# EQEP0_REG register map
Vendor: Texas Instruments
Peripheral module from a debugger description file (folder am65x).
Registers are 32-bit, read-write, reset 0x0 unless marked. A register's access mark holds for its fields unless they carry their own. Offsets are as the file gives them; lines under a group give offsets from that group; [hi:lo] are bit positions; {n}, {i} and the like mark numbered series; 'fields as' and 'values as' point back to an identical list; <NAME> marks a mode.

## EQEP0_REG
0x00 EQEP_QPOSCNT
  [31:0] QPOSCNT — This 32 bit position counter register counts up/down on every EQEP pulse based on direction input. This counter acts as a position integrator whose count value is proportional to position from a give reference point.
0x04 EQEP_QPOSINIT
  [31:0] QPOSINIT — This register contains the position value that is used to initialize the position counter based on external strobe or index event. The position counter can be initialized through software.
0x08 EQEP_QPOSMAX
  [31:0] QPOSMAX — This register contains the maximum position counter value.
0x0C EQEP_QPOSCMP
  [31:0] QPOSCMP — The position-compare value in this register is compared with the position counter (
0x10 EQEP_QPOSILAT ro
  [31:0] QPOSILAT — The position-counter value is latched into this register on an index event as defined by the
0x14 EQEP_QPOSSLAT ro
  [31:0] QPOSSLAT — The position-counter value is latched into this register on strobe event as defined by the
0x18 EQEP_QPOSLAT ro
  [31:0] QPOSLAT — The position-counter value is latched into this register on unit time out event.
0x1C EQEP_QUTMR
  [31:0] QUTMR — This register acts as time base for unit time event generation. When this timer value matches with unit time period value, unit time event is generated.
0x20 EQEP_QUPRD
  [31:0] QUPRD — This register contains the period count for unit timer to generate periodic unit time events to latch the EQEP position information at periodic interval and optionally to generate interrupt.
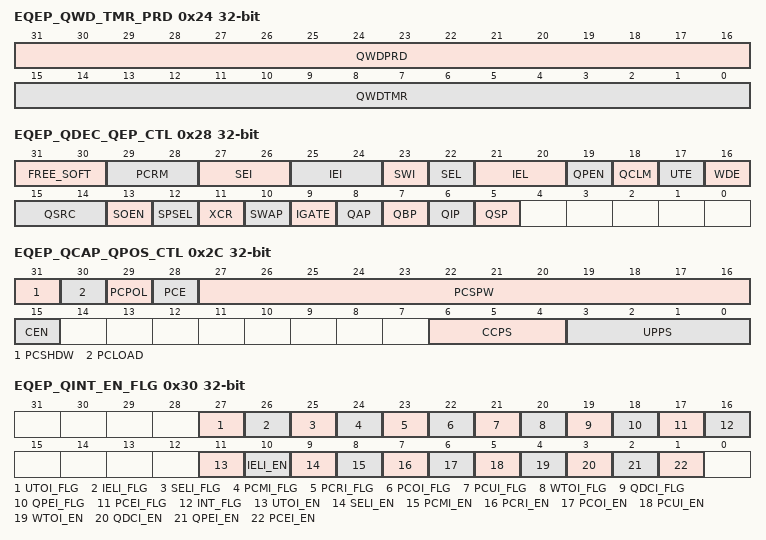
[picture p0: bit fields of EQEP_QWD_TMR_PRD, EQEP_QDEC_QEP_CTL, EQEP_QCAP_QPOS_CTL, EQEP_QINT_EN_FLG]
0x24 EQEP_QWD_TMR_PRD
  [31:16] QWDPRD — This field contains the time-out count for the EQEP peripheral watch dog timer. When the watch dog timer value matches with the watch dog period value, status flag is set to indicate the stall.
  [15:0] QWDTMR — This field acts as time base for watch dog to detect motor stalls. When this timer value matches with watch dog period value, watch dog timeout interrupt is generated. This register is reset upon edge transition in quadrature-clock indicating the motion.
0x28 EQEP_QDEC_QEP_CTL access per field
  [31:30] FREE_SOFT rw — Emulation Control Bits. In the values 0 through 3 listed below, x is different for the four following behaviors. EQEP_QPOSCNT behavior, x refers to the Position counter. EQEP_QWD_TMR_PRD behavior, x refers to the Watchdog counter. EQEP_QUTMR behavior, x refers to the Unit timer. EQEP_QCTMR behavior, x refers to the Capture timer. 0h = x stops immediately. For 1h = For QCTMR behavior, x continues to count until the next unit period event. 2h = x is unaffected by emulation suspend. 3h = x is unaffected by emulation suspend.
  [29:28] PCRM rw — Position counter reset mode 0h = Position counter reset on an index event 1h = Position counter reset on the maximum position 2h = Position counter resets once on the first index event 3h = Position counter reset on a unit time event
  [27:26] SEI rw — Strobe event initialization of position counter 0h = Does nothing (action disabled) 1h = Does nothing (action disabled) 2h = Initializes the position counter on rising edge of the QEPS signal 3h = Clockwise Direction: Initializes the position counter on the rising edge of QEPS strobe. Counter Clockwise Direction: Initializes the position counter on the falling edge of QEPS strobe
  [25:24] IEI rw — Index event initialization of position counter 0h = Do nothing (action disabled) 1h = Do nothing (action disabled) 2h = Initializes the position counter on the rising edge of the QEPI signal (QPOSCNT = QPOSINIT) 3h = Initializes the position counter on the falling edge of QEPI signal (QPOSCNT = QPOSINIT)
  [23] SWI rw — Software initialization of position counter 0h = Do nothing (action disabled) 1h = Initialize position counter, this bit is cleared automatically
  [22] SEL rw — Strobe event latch of position counter 0h = The position counter is latched on the rising edge of QEPS strobe (QPOSSLAT = POSCCNT). Latching on the falling edge can be done by inverting the strobe input using the QSP bit in the 1h = Clockwise Direction: Position counter is latched on rising edge of QEPS strobe. Counter Clockwise Direction: Position counter is latched on falling edge of QEPS strobe.
  [21:20] IEL rw — Index event latch of position counter (software index marker) 0h = Reserved 1h = Latches position counter on rising edge of the index signal 2h = Latches position counter on falling edge of the index signal 3h = Software index marker. Latches the position counter and quadrature direction flag on index event marker. The position counter is latched to theEQEP_QPOSILAT register and the direction flag is latched in the EQEP_QEPSTS[QDLF] bit. This mode is useful for software index marking.
  [19] QPEN rw — Quadrature position counter enable/software reset 0h = Reset the EQEP peripheral internal operating flags/read-only registers. Control/configuration registers are not disturbed by a software reset. 1h = EQEP position counter is enabled
  [18] QCLM rw — EQEP capture latch mode 0h = Latch on position counter read by CPU. Capture timer and capture period values are latched into EQEP_QCTMRLAT and EQEP_QCPRDLAT registers when CPU reads the EQEP_QPOSCNT register. 1h = Latch on unit time out. Position counter, capture timer and capture period values are latched intoEQEP_QPOSLAT, EQEP_QCTMRLAT and EQEP_QCPRDLAT registers on unit time out.
  [17] UTE rw — EQEP unit timer enable 0h = Disable EQEP unit timer 1h = Enable unit timer
  [16] WDE rw — EQEP watchdog enable 0h = Disable the EQEP watchdog timer 1h = Enable the EQEP watchdog timer
  [15:14] QSRC rw — Position-counter source selection. 0h = Quadrature count mode (QCLK = iCLK, QDIR = iDIR) 1h = Direction-count mode (QCLK = xCLK, QDIR = xDIR) 2h = UP count mode for frequency measurement (QCLK = xCLK, QDIR = 1) 3h = DOWN count mode for frequency measurement (QCLK = xCLK, QDIR = 0)
  [13] SOEN rw — Sync output-enable 0h = Disable position-compare sync output 1h = Enable position-compare sync output
  [12] SPSEL rw — Sync output pin selection 0h = Index pin is used for sync output 1h = Strobe pin is used for sync output
  [11] XCR rw — External clock rate 0h = 2x resolution: Count the rising/falling edge 1h = 1x resolution: Count the rising edge only
  [10] SWAP rw — Swap quadrature clock inputs. This swaps the input to the quadrature decoder, reversing the counting direction. 0h = Quadrature-clock inputs are not swapped 1h = Quadrature-clock inputs are swapped
  [9] IGATE rw — Index pulse gating option 0h = Disable gating of Index pulse 1h = Gate the index pin with strobe
  [8] QAP rw — QEPA input polarity 0h = No effect 1h = Negates QEPA input
  [7] QBP rw — QEPB input polarity 0h = No effect 1h = Negates QEPB input
  [6] QIP rw — QEPI input polarity 0h = No effect 1h = Negates QEPI input
  [5] QSP rw — QEPS input polarity 0h = No effect 1h = Negates QEPS input
0x2C EQEP_QCAP_QPOS_CTL access per field
  [31] PCSHDW rw — Position-compare shadow enable 0h = Shadow disabled, load Immediate 1h = Shadow enabled
  [30] PCLOAD rw — Position-compare shadow load mode 0h = Load on QPOSCNT = 0 1h = Load when QPOSCNT = QPOSCMP
  [29] PCPOL rw — Polarity of sync output 0h = Active HIGH pulse output 1h = Active LOW pulse output
  [28] PCE rw — Position-compare enable/disable 0h = Disable position compare unit 1h = Enable position compare unit
  [27:16] PCSPW rw — Select-position-compare sync output pulse width ... 0h = 1 × 4 × EQEP_FICLK cycles 1h = 2 × 4 × EQEP_FICLK cycles 2h = 3 × 4 × EQEP_FICLK cycles to 4096 × 4 × EQEP_FICLK cycles FFFh = 3 × 4 × EQEP_FICLK cycles to 4096 × 4 × EQEP_FICLK cycles
  [15] CEN rw — Enable EQEP capture 0h = EQEP capture unit is disabled 1h = EQEP capture unit is enabled
  [6:4] CCPS rw — EQEP capture timer clock prescaler 0h = CAPCLK = EQEP_FICLK/1 1h = CAPCLK = EQEP_FICLK/2 2h = CAPCLK = EQEP_FICLK/4 3h = CAPCLK = EQEP_FICLK/8 4h = CAPCLK = EQEP_FICLK/16 5h = CAPCLK = EQEP_FICLK/32 6h = CAPCLK = EQEP_FICLK/64 7h = CAPCLK = EQEP_FICLK/128
  [3:0] UPPS rw — Unit position event prescaler 0h = UPEVNT = QCLK/1 1h = UPEVNT = QCLK/2 2h = UPEVNT = QCLK/4 3h = UPEVNT = QCLK/8 4h = UPEVNT = QCLK/16 5h = UPEVNT = QCLK/32 6h = UPEVNT = QCLK/64 7h = UPEVNT = QCLK/128 8h = UPEVNT = QCLK/256 9h = UPEVNT = QCLK/512 Ah = UPEVNT = QCLK/1024 Bh = UPEVNT = QCLK/2048 Ch = Reserved Dh = Reserved Eh = Reserved Fh = Reserved
0x30 EQEP_QINT_EN_FLG access per field
  [27] UTOI_FLG ro — Unit time out interrupt flag 0h = No interrupt generated 1h = Set by EQEP unit timer period match
  [26] IELI_FLG ro — Index event latch interrupt flag 0h = No interrupt generated 1h = This bit is set after latching the
  [25] SELI_FLG ro — Strobe event latch interrupt flag 0h = No interrupt generated 1h = This bit is set after latching theEQEP_QPOSSLAT
  [24] PCMI_FLG ro — EQEP compare match event interrupt flag 0h = No interrupt generated 1h = This bit is set on position-compare match
  [23] PCRI_FLG ro — Position-compare ready interrupt flag 0h = No interrupt generated 1h = This bit is set after transferring the shadow register value to the active position compare register.
  [22] PCOI_FLG ro — Position counter overflow interrupt flag 0h = No interrupt generated 1h = This bit is set on position counter overflow.
  [21] PCUI_FLG ro — Position counter underflow interrupt flag 0h = No interrupt generated 1h = This bit is set on position counter underflow.
  [20] WTOI_FLG ro — Watchdog timeout interrupt flag 0h = No interrupt generated 1h = Set by watch dog timeout
  [19] QDCI_FLG ro — Quadrature direction change interrupt flag 0h = No interrupt generated 1h = This bit is set during change of direction
  [18] QPEI_FLG ro — Quadrature phase error interrupt flag 0h = No interrupt generated 1h = Set on simultaneous transition of QEPA and QEPB
  [17] PCEI_FLG ro — Position counter error interrupt flag 0h = No interrupt generated 1h = Position counter error
  [16] INT_FLG ro — Global interrupt status flag 0h = No interrupt generated 1h = Interrupt was generated
  [11] UTOI_EN rw — Unit time out interrupt enable 0h = Interrupt is disabled 1h = Interrupt is enabled
  [10] IELI_EN rw — Index event latch interrupt enable 0h = Interrupt is disabled 1h = Interrupt is enabled
  [9] SELI_EN rw — Strobe event latch interrupt enable 0h = Interrupt is disabled 1h = Interrupt is enabled
  [8] PCMI_EN rw — Position-compare match interrupt enable 0h = Interrupt is disabled 1h = Interrupt is enabled
  [7] PCRI_EN rw — Position-compare ready interrupt enable 0h = Interrupt is disabled 1h = Interrupt is enabled
  [6] PCOI_EN rw — Position counter overflow interrupt enable 0h = Interrupt is disabled 1h = Interrupt is enabled
  [5] PCUI_EN rw — Position counter underflow interrupt enable 0h = Interrupt is disabled 1h = Interrupt is enabled
  [4] WTOI_EN rw — Watchdog time out interrupt enable 0h = Interrupt is disabled 1h = Interrupt is enabled
  [3] QDCI_EN rw — Quadrature direction change interrupt enable 0h = Interrupt is disabled 1h = Interrupt is enabled
  [2] QPEI_EN rw — Quadrature phase error interrupt enable 0h = Interrupt is disabled 1h = Interrupt is enabled
  [1] PCEI_EN rw — Position counter error interrupt enable 0h = Interrupt is disabled 1h = Interrupt is enabled
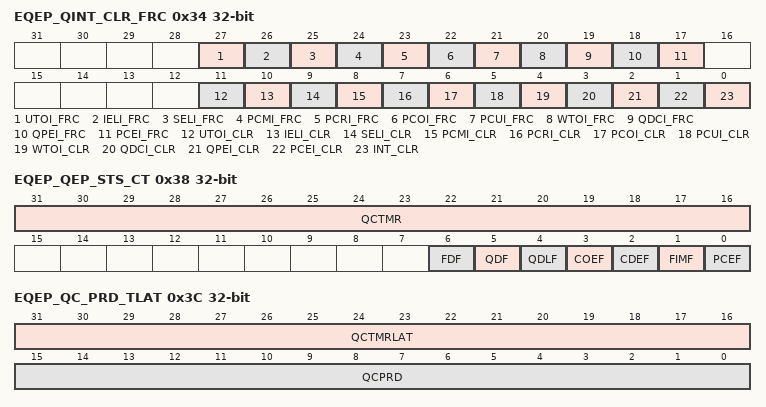
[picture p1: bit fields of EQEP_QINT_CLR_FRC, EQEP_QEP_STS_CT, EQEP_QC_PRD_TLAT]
0x34 EQEP_QINT_CLR_FRC access not given
  [27] UTOI_FRC — Force unit time out interrupt Read 0h = No effect Write 1h = Force the interrupt (access RW1S)
  [26] IELI_FRC — Force index event latch interrupt Read 0h = No effect Write 1h = Force the interrupt (access RW1S)
  [25] SELI_FRC — Force strobe event latch interrupt Read 0h = No effect Write 1h = Force the interrupt (access RW1S)
  [24] PCMI_FRC — Force position-compare match interrupt Read 0h = No effect Write 1h = Force the interrupt (access RW1S)
  [23] PCRI_FRC — Force position-compare ready interrupt Read 0h = No effect Write 1h = Force the interrupt (access RW1S)
  [22] PCOI_FRC — Force position counter overflow interrupt Read 0h = No effect Write 1h = Force the interrupt (access RW1S)
  [21] PCUI_FRC — Force position counter underflow interrupt Read 0h = No effect Write 1h = Force the interrupt (access RW1S)
  [20] WTOI_FRC — Force watchdog time out interrupt Read 0h = No effect Write 1h = Force the interrupt (access RW1S)
  [19] QDCI_FRC — Force quadrature direction change interrupt Read 0h = No effect Write 1h = Force the interrupt (access RW1S)
  [18] QPEI_FRC — Force quadrature phase error interrupt Read 0h = No effect Write 1h = Force the interrupt (access RW1S)
  [17] PCEI_FRC — Force position counter error interrupt Read 0h = No effect Write 1h = Force the interrupt (access RW1S)
  [11] UTOI_CLR — Clear unit time out interrupt flag Read 0h = No effect Write 1h = Clears the interrupt flag (access RW1C)
  [10] IELI_CLR — Clear index event latch interrupt flag Read 0h = No effect Write 1h = Clears the interrupt flag (access RW1C)
  [9] SELI_CLR — Clear strobe event latch interrupt flag Read 0h = No effect Write 1h = Clears the interrupt flag (access RW1C)
  [8] PCMI_CLR — Clear EQEP compare match event interrupt flag Read 0h = No effect Write 1h = Clears the interrupt flag (access RW1C)
  [7] PCRI_CLR — Clear position-compare ready interrupt flag Read 0h = No effect Write 1h = Clears the interrupt flag (access RW1C)
  [6] PCOI_CLR — Clear position counter overflow interrupt flag Read 0h = No effect Write 1h = Clears the interrupt flag (access RW1C)
  [5] PCUI_CLR — Clear position counter underflow interrupt flag Read 0h = No effect Write 1h = Clears the interrupt flag (access RW1C)
  [4] WTOI_CLR — Clear watchdog timeout interrupt flag Read 0h = No effect Write 1h = Clears the interrupt flag (access RW1C)
  [3] QDCI_CLR — Clear quadrature direction change interrupt flag Read 0h = No effect Write 1h = Clears the interrupt flag (access RW1C)
  [2] QPEI_CLR — Clear quadrature phase error interrupt flag Read 0h = No effect Write 1h = Clears the interrupt flag (access RW1C)
  [1] PCEI_CLR — Clear position counter error interrupt flag Read 0h = No effect Write 1h = Clears the interrupt flag (access RW1C)
  [0] INT_CLR — Global interrupt clear flag Read 0h = No effect Write 1h = Clears the interrupt flag and enables further interrupts to be generated if an event flags is set to 1. (access RW1C)
0x38 EQEP_QEP_STS_CT access not given
  [31:16] QCTMR rw — This field provides time base for edge capture unit.
  [6] FDF ro — Direction on the first index marker. Status of the direction is latched on the first index event marker. 0h = Counter-clockwise rotation (or reverse movement) on the first index event 1h = Clockwise rotation (or forward movement) on the first index event
  [5] QDF ro — Quadrature direction flag 0h = Counter-clockwise rotation (or reverse movement) 1h = Clockwise rotation (or forward movement)
  [4] QDLF ro — EQEP direction latch flag. Status of direction is latched on every index event marker. 0h = Counter-clockwise rotation (or reverse movement) on index event marker 1h = Clockwise rotation (or forward movement) on index event marker
  [3] COEF — Capture overflow error flag 0h = Sticky bit, cleared by writing 1 1h = Overflow occurred in EQEP Capture timer (QEPCTMR) (access RW1C)
  [2] CDEF — Capture direction error flag 0h = Sticky bit, cleared by writing 1 1h = Direction change occurred between the capture position event. (access RW1C)
  [1] FIMF — First index marker flag 0h = Sticky bit, cleared by writing 1 1h = Set by first occurrence of index pulse (access RW1C)
  [0] PCEF ro — Position counter error flag. This bit is not sticky and it is updated for every index event. 0h = No error occurred during the last index transition. 1h = Position counter error
0x3C EQEP_QC_PRD_TLAT access per field
  [31:16] QCTMRLAT ro — The EQEP capture timer value can be latched into this register on two events:
  [15:0] QCPRD rw — This register holds the period count value between the last successive EQEP position events.
0x40 EQEP_QCPRDLAT 16-bit
  [15:0] QCPRDLAT — The EQEP capture period value can be latched into this register on two events:
0x5C EQEP_REVID ro reset 0x44D31903
  [31:0] REVISION — IP Revision
